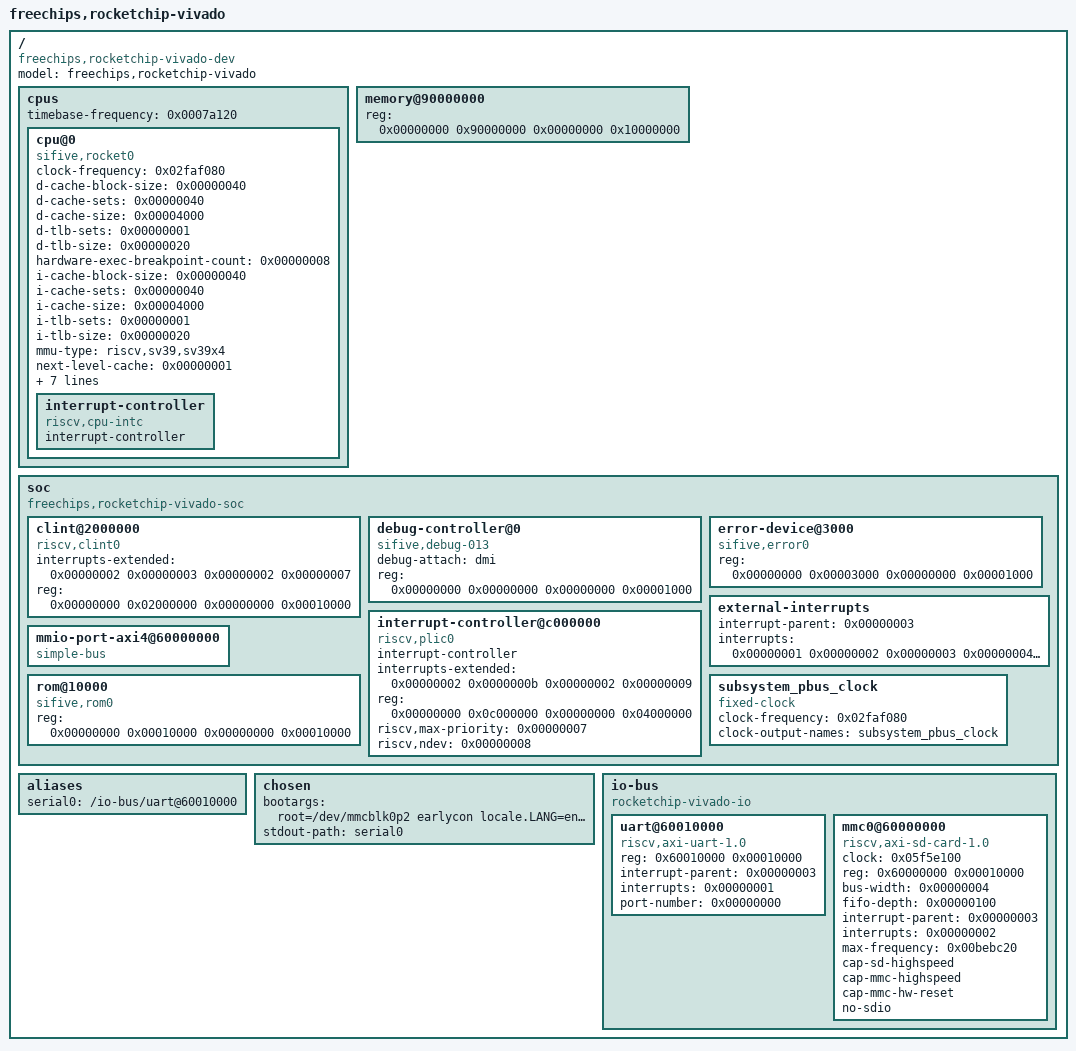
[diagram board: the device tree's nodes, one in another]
// /dts-v1/;
// 
// / {
// 	#address-cells = <0x02>;
// 	#size-cells = <0x02>;
// 	compatible = "riscv-virtio";
// 	model = "riscv-virtio,qemu";
// 
// 	poweroff {
// 		value = <0x5555>;
// 		offset = <0x00>;
// 		regmap = <0x04>;
// 		compatible = "syscon-poweroff";
// 	};
// 
// 	reboot {
// 		value = <0x7777>;
// 		offset = <0x00>;
// 		regmap = <0x04>;
// 		compatible = "syscon-reboot";
// 	};
// 
// 	platform-bus@4000000 {
// 		interrupt-parent = <0x03>;
// 		ranges = <0x00 0x00 0x4000000 0x2000000>;
// 		#address-cells = <0x01>;
// 		#size-cells = <0x01>;
// 		compatible = "qemu,platform", "simple-bus";
// 	};
// 
// 	memory@90000000 {
// 		device_type = "memory";
// 		reg = <0x00 0x90000000 0x00 0x10000000>;
// 	};
// 
// 	cpus {
// 		#address-cells = <0x01>;
// 		#size-cells = <0x00>;
// 		timebase-frequency = <0x989680>;
// 
// 		cpu@0 {
// 			phandle = <0x01>;
// 			device_type = "cpu";
// 			reg = <0x00>;
// 			status = "okay";
// 			compatible = "riscv";
// 			riscv,cbop-block-size = <0x40>;
// 			riscv,cboz-block-size = <0x40>;
// 			riscv,cbom-block-size = <0x40>;
// 			riscv,isa-extensions = "i", "m", "a", "f", "d", "c", "h", "zic64b", "zicbom", "zicbop", "zicboz", "ziccamoa", "ziccif", "zicclsm", "ziccrse", "zicfiss", "zicntr", "zicsr", "zifencei", "zihintntl", "zihintpause", "zihpm", "zmmul", "za64rs", "zaamo", "zalrsc", "zawrs", "zfa", "zca", "zcd", "zba", "zbb", "zbc", "zbs", "ssccptr", "sscounterenw", "sstc", "sstvala", "sstvecd", "svadu";
// 			riscv,isa-base = "rv64i";
// 			riscv,isa = "rv64imafdch_zic64b_zicbom_zicbop_zicboz_ziccamoa_ziccif_zicclsm_ziccrse_zicfiss_zicntr_zicsr_zifencei_zihintntl_zihintpause_zihpm_zmmul_za64rs_zaamo_zalrsc_zawrs_zfa_zca_zcd_zba_zbb_zbc_zbs_ssccptr_sscounterenw_sstc_sstvala_sstvecd_svadu";
// 			mmu-type = "riscv,sv57";
// 
// 			interrupt-controller {
// 				#interrupt-cells = <0x01>;
// 				interrupt-controller;
// 				compatible = "riscv,cpu-intc";
// 				phandle = <0x02>;
// 			};
// 		};
// 
// 		cpu-map {
// 
// 			cluster0 {
// 
// 				core0 {
// 					cpu = <0x01>;
// 				};
// 			};
// 		};
// 	};
// 
// 	pmu {
// 		riscv,event-to-mhpmcounters = <0x01 0x01 0x7fff9 0x02 0x02 0x7fffc 0x10019 0x10019 0x7fff8 0x1001b 0x1001b 0x7fff8 0x10021 0x10021 0x7fff8>;
// 		compatible = "riscv,pmu";
// 	};
// 
// 	fw-cfg@10100000 {
// 		dma-coherent;
// 		reg = <0x00 0x10100000 0x00 0x18>;
// 		compatible = "qemu,fw-cfg-mmio";
// 	};
// 
// 	flash@20000000 {
// 		bank-width = <0x04>;
// 		reg = <0x00 0x20000000 0x00 0x2000000 0x00 0x22000000 0x00 0x2000000>;
// 		compatible = "cfi-flash";
// 	};
// 
// 	chosen {
// 		bootargs = "root=/dev/sda2 locale.LANG=en_US.UTF-8";
// 		stdout-path = "/soc/serial@10000000";
// 		rng-seed = <0x9775b34d 0xe39158f2 0x3e9d10b1 0x73692dfd 0x13c15814 0xa4ad203f 0x8b0d62f7 0x6bf8a79d>;
// 	};
// 
// 	soc {
// 		#address-cells = <0x02>;
// 		#size-cells = <0x02>;
// 		compatible = "simple-bus";
// 		ranges;
// 
// 		rtc@101000 {
// 			interrupts = <0x0b>;
// 			interrupt-parent = <0x03>;
// 			reg = <0x00 0x101000 0x00 0x1000>;
// 			compatible = "google,goldfish-rtc";
// 		};
// 
// 		serial@10000000 {
// 			interrupts = <0x0a>;
// 			interrupt-parent = <0x03>;
// 			clock-frequency = "", "8@";
// 			reg = <0x00 0x10000000 0x00 0x100>;
// 			compatible = "ns16550a";
// 		};
// 
// 		test@100000 {
// 			phandle = <0x04>;
// 			reg = <0x00 0x100000 0x00 0x1000>;
// 			compatible = "sifive,test1", "sifive,test0", "syscon";
// 		};
// 
// 		virtio_mmio@10008000 {
// 			interrupts = <0x08>;
// 			interrupt-parent = <0x03>;
// 			reg = <0x00 0x10008000 0x00 0x1000>;
// 			compatible = "virtio,mmio";
// 		};
// 
// 		virtio_mmio@10007000 {
// 			interrupts = <0x07>;
// 			interrupt-parent = <0x03>;
// 			reg = <0x00 0x10007000 0x00 0x1000>;
// 			compatible = "virtio,mmio";
// 		};
// 
// 		virtio_mmio@10006000 {
// 			interrupts = <0x06>;
// 			interrupt-parent = <0x03>;
// 			reg = <0x00 0x10006000 0x00 0x1000>;
// 			compatible = "virtio,mmio";
// 		};
// 
// 		virtio_mmio@10005000 {
// 			interrupts = <0x05>;
// 			interrupt-parent = <0x03>;
// 			reg = <0x00 0x10005000 0x00 0x1000>;
// 			compatible = "virtio,mmio";
// 		};
// 
// 		virtio_mmio@10004000 {
// 			interrupts = <0x04>;
// 			interrupt-parent = <0x03>;
// 			reg = <0x00 0x10004000 0x00 0x1000>;
// 			compatible = "virtio,mmio";
// 		};
// 
// 		virtio_mmio@10003000 {
// 			interrupts = <0x03>;
// 			interrupt-parent = <0x03>;
// 			reg = <0x00 0x10003000 0x00 0x1000>;
// 			compatible = "virtio,mmio";
// 		};
// 
// 		virtio_mmio@10002000 {
// 			interrupts = <0x02>;
// 			interrupt-parent = <0x03>;
// 			reg = <0x00 0x10002000 0x00 0x1000>;
// 			compatible = "virtio,mmio";
// 		};
// 
// 		virtio_mmio@10001000 {
// 			interrupts = <0x01>;
// 			interrupt-parent = <0x03>;
// 			reg = <0x00 0x10001000 0x00 0x1000>;
// 			compatible = "virtio,mmio";
// 		};
// 
// 		plic@c000000 {
// 			phandle = <0x03>;
// 			riscv,ndev = <0x5f>;
// 			reg = <0x00 0xc000000 0x00 0x600000>;
// 			interrupts-extended = <0x02 0x0b 0x02 0x09>;
// 			interrupt-controller;
// 			compatible = "sifive,plic-1.0.0", "riscv,plic0";
// 			#address-cells = <0x00>;
// 			#interrupt-cells = <0x01>;
// 		};
// 
// 		clint@2000000 {
// 			interrupts-extended = <0x02 0x03 0x02 0x07>;
// 			reg = <0x00 0x2000000 0x00 0x10000>;
// 			compatible = "sifive,clint0", "riscv,clint0";
// 		};
// 
// 		pci@30000000 {
// 			interrupt-map-mask = <0x1800 0x00 0x00 0x07>;
// 			interrupt-map = <0x00 0x00 0x00 0x01 0x03 0x20 0x00 0x00 0x00 0x02 0x03 0x21 0x00 0x00 0x00 0x03 0x03 0x22 0x00 0x00 0x00 0x04 0x03 0x23 0x800 0x00 0x00 0x01 0x03 0x21 0x800 0x00 0x00 0x02 0x03 0x22 0x800 0x00 0x00 0x03 0x03 0x23 0x800 0x00 0x00 0x04 0x03 0x20 0x1000 0x00 0x00 0x01 0x03 0x22 0x1000 0x00 0x00 0x02 0x03 0x23 0x1000 0x00 0x00 0x03 0x03 0x20 0x1000 0x00 0x00 0x04 0x03 0x21 0x1800 0x00 0x00 0x01 0x03 0x23 0x1800 0x00 0x00 0x02 0x03 0x20 0x1800 0x00 0x00 0x03 0x03 0x21 0x1800 0x00 0x00 0x04 0x03 0x22>;
// 			ranges = <0x1000000 0x00 0x00 0x00 0x3000000 0x00 0x10000 0x2000000 0x00 0x40000000 0x00 0x40000000 0x00 0x40000000 0x3000000 0x04 0x00 0x04 0x00 0x04 0x00>;
// 			reg = <0x00 0x30000000 0x00 0x10000000>;
// 			dma-coherent;
// 			bus-range = <0x00 0xff>;
// 			linux,pci-domain = <0x00>;
// 			device_type = "pci";
// 			compatible = "pci-host-ecam-generic";
// 			#size-cells = <0x02>;
// 			#interrupt-cells = <0x01>;
// 			#address-cells = <0x03>;
// 		};
// 	};
// };

/dts-v1/;
/ {
	#address-cells = <0x00000002>;
	#size-cells = <0x00000002>;
	compatible = "freechips,rocketchip-vivado-dev";
	model = "freechips,rocketchip-vivado";
	cpus {
		#address-cells = <0x00000001>;
		#size-cells = <0x00000000>;
		timebase-frequency = <0x0007a120>;
		cpu@0 {
			clock-frequency = <0x02faf080>;
			compatible = "sifive,rocket0", "riscv";
			d-cache-block-size = <0x00000040>;
			d-cache-sets = <0x00000040>;
			d-cache-size = <0x00004000>;
			d-tlb-sets = <0x00000001>;
			d-tlb-size = <0x00000020>;
			device_type = "cpu";
			hardware-exec-breakpoint-count = <0x00000008>;
			i-cache-block-size = <0x00000040>;
			i-cache-sets = <0x00000040>;
			i-cache-size = <0x00004000>;
			i-tlb-sets = <0x00000001>;
			i-tlb-size = <0x00000020>;
			mmu-type = "riscv,sv39,sv39x4";
			next-level-cache = <0x00000001>;
			reg = <0x00000000>;
			riscv,isa = "rv64imafdchzicsr_zifencei_zihpm_xrocket";
			riscv,pmpgranularity = <0x00001000>;
			riscv,pmpregions = <0x00000008>;
			status = "okay";
			timebase-frequency = <0x0007a120>;
			tlb-split;
			interrupt-controller {
				#interrupt-cells = <0x00000001>;
				compatible = "riscv,cpu-intc";
				interrupt-controller;
				phandle = <0x00000002>;
			};
		};
	};
	memory@90000000 {
		device_type = "memory";
		reg = <0x00000000 0x90000000 0x00000000 0x10000000>;
		phandle = <0x00000001>;
	};
	soc {
		#address-cells = <0x00000002>;
		#size-cells = <0x00000002>;
		compatible = "freechips,rocketchip-vivado-soc", "simple-bus";
		ranges;
		clint@2000000 {
			compatible = "riscv,clint0";
			interrupts-extended = <0x00000002 0x00000003 0x00000002 0x00000007>;
			reg = <0x00000000 0x02000000 0x00000000 0x00010000>;
			reg-names = "control";
		};
		debug-controller@0 {
			compatible = "sifive,debug-013", "riscv,debug-013";
			debug-attach = "dmi";
			reg = <0x00000000 0x00000000 0x00000000 0x00001000>;
			reg-names = "control";
		};
		error-device@3000 {
			compatible = "sifive,error0";
			reg = <0x00000000 0x00003000 0x00000000 0x00001000>;
		};
		external-interrupts {
			interrupt-parent = <0x00000003>;
			interrupts = <0x00000001 0x00000002 0x00000003 0x00000004 0x00000005 0x00000006 0x00000007 0x00000008>;
		};
		interrupt-controller@c000000 {
			#interrupt-cells = <0x00000001>;
			compatible = "riscv,plic0";
			interrupt-controller;
			interrupts-extended = <0x00000002 0x0000000b 0x00000002 0x00000009>;
			reg = <0x00000000 0x0c000000 0x00000000 0x04000000>;
			reg-names = "control";
			riscv,max-priority = <0x00000007>;
			riscv,ndev = <0x00000008>;
			phandle = <0x00000003>;
		};
		mmio-port-axi4@60000000 {
			#address-cells = <0x00000001>;
			#size-cells = <0x00000001>;
			compatible = "simple-bus";
			ranges = <0x60000000 0x00000000 0x60000000 0x20000000>;
		};
		rom@10000 {
			compatible = "sifive,rom0";
			reg = <0x00000000 0x00010000 0x00000000 0x00010000>;
			reg-names = "mem";
		};
		subsystem_pbus_clock {
			#clock-cells = <0x00000000>;
			clock-frequency = <0x02faf080>;
			clock-output-names = "subsystem_pbus_clock";
			compatible = "fixed-clock";
		};
	};
	aliases {
		serial0 = "/io-bus/uart@60010000";
	};
	chosen {
 		bootargs = "root=/dev/mmcblk0p2 earlycon locale.LANG=en_US.UTF-8";
		stdout-path = "serial0";
	};
	io-bus {
		#address-cells = <0x00000001>;
		#size-cells = <0x00000001>;
		compatible = "rocketchip-vivado-io", "simple-bus";
		ranges;
		uart@60010000 {
			compatible = "riscv,axi-uart-1.0";
			reg = <0x60010000 0x00010000>;
			interrupt-parent = <0x00000003>;
			interrupts = <0x00000001>;
			port-number = <0x00000000>;
		};
		mmc0@60000000 {
			compatible = "riscv,axi-sd-card-1.0";
			clock = <0x05f5e100>;
			reg = <0x60000000 0x00010000>;
			bus-width = <0x00000004>;
			fifo-depth = <0x00000100>;
			interrupt-parent = <0x00000003>;
			interrupts = <0x00000002>;
			max-frequency = <0x00bebc20>;
			cap-sd-highspeed;
			cap-mmc-highspeed;
			cap-mmc-hw-reset;
			no-sdio;
		};
		//eth0@60020000 {
		//	compatible = "riscv,axi-ethernet-1.0";
		//	reg = <0x60020000 0x00010000>;
		//	phy-mode = "rgmii";
		//	local-mac-address = [00 0a 35 00 00 01];
		//	interrupt-parent = <0x00000003>;
		//	interrupts = <0x00000003>;
		//};
	};
};
